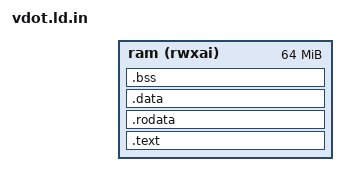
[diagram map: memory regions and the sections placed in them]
/* =========================================================================
 * vdot.ld.in —— 链接脚本模板。@MBASE@ 由 Makefile 用 NEMU 实际构建配置中的
 * CONFIG_MBASE 替换。NEMU 把 image 原样读入 pmem 起始处
 * （src/monitor/image_loader.c:281-282），故产物必须是 objcopy 出来的扁平
 * binary，且第一条指令就是 _start。
 *
 * 与 tests/riscv/hello 的唯一差别：语料 blob（约 2.7 MB）放在 .rodata 里，
 * 因此 RAM 窗口放宽到 64 MiB。
 * ========================================================================= */
OUTPUT_ARCH(riscv)
ENTRY(_start)

MEMORY {
  ram (rwxai) : ORIGIN = @MBASE@, LENGTH = 64M
}

SECTIONS {
  . = @MBASE@;

  .text : {
    *(.text.init)        /* _start 必须排在最前 */
    *(.text .text.*)
  } > ram

  .rodata : {
    . = ALIGN(16);
    *(.rodata.corpus)    /* .incbin 进来的共享语料 */
    *(.rodata .rodata.*) *(.srodata .srodata.*)
  } > ram

  .data : {
    . = ALIGN(8);
    _gp = . + 0x800;
    *(.data .data.*)
    *(.sdata .sdata.*)
  } > ram

  . = ALIGN(8);
  _bss_start = .;
  .bss : { *(.bss .bss.*) *(.sbss .sbss.*) *(COMMON) } > ram
  . = ALIGN(8);
  _bss_end = .;

  . = ALIGN(16);
  . = . + 0x10000;        /* 64 KiB 栈 */
  _stack_top = .;

  /DISCARD/ : { *(.comment) *(.note*) *(.eh_frame*) *(.riscv.attributes) }
}
